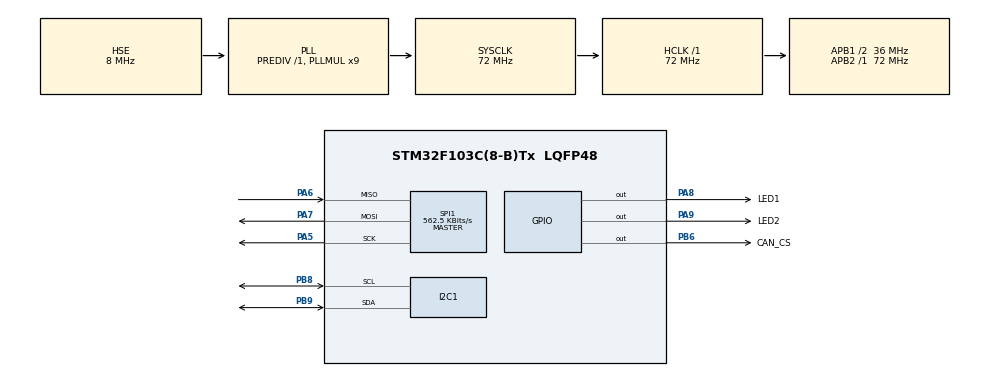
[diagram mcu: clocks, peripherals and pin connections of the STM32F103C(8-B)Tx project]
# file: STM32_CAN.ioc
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Mcu.Family=STM32F1
Mcu.Name=STM32F103C(8-B)Tx
Mcu.Package=LQFP48
NVIC.PriorityGroup=NVIC_PRIORITYGROUP_4
PA5.Mode=Full_Duplex_Master
PA5.Signal=SPI1_SCK
PA6.Mode=Full_Duplex_Master
PA6.Signal=SPI1_MISO
PA7.Mode=Full_Duplex_Master
PA7.Signal=SPI1_MOSI
PA8.GPIO_Label=LED1
PA8.PinState=GPIO_PIN_RESET
PA8.Signal=GPIO_Output
PA9.GPIO_Label=LED2
PA9.Signal=GPIO_Output
PB6.GPIO_Label=CAN_CS
PB6.PinState=GPIO_PIN_SET
PB6.Signal=GPIO_Output
PB8.Mode=I2C
PB8.Signal=I2C1_SCL
PB9.Mode=I2C
PB9.Signal=I2C1_SDA
PD0-OSC_IN.Mode=HSE-External-Oscillator
PD0-OSC_IN.Signal=RCC_OSC_IN
PD1-OSC_OUT.Mode=HSE-External-Oscillator
PD1-OSC_OUT.Signal=RCC_OSC_OUT
ProjectManager.HeapSize=0x200
ProjectManager.StackSize=0x400
ProjectManager.TargetToolchain=STM32CubeIDE
RCC.AHBFreq_Value=72000000
RCC.APB1CLKDivider=RCC_HCLK_DIV2
RCC.APB1Freq_Value=36000000
RCC.APB1TimFreq_Value=72000000
RCC.APB2Freq_Value=72000000
RCC.APB2TimFreq_Value=72000000
RCC.HCLKFreq_Value=72000000
RCC.PLLMUL=RCC_PLL_MUL9
RCC.PLLSourceVirtual=RCC_PLLSOURCE_HSE
RCC.SYSCLKFreq_VALUE=72000000
RCC.SYSCLKSource=RCC_SYSCLKSOURCE_PLLCLK
RCC.USBFreq_Value=72000000
SPI1.BaudRatePrescaler=SPI_BAUDRATEPRESCALER_128
SPI1.CalculateBaudRate=562.5 KBits/s
SPI1.Direction=SPI_DIRECTION_2LINES
SPI1.Mode=SPI_MODE_MASTER
SPI1.VirtualType=VM_MASTER
VP_SYS_VS_ND.Mode=No_Debug
board=custom

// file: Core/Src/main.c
/* USER CODE BEGIN Header */
/**
 ******************************************************************************
 * @file           : main.c
 * @brief          : Main program body
 ******************************************************************************
 * @attention
 *
 * Copyright (c) 2024 STMicroelectronics.
 * All rights reserved.
 *
 * This software is licensed under terms that can be found in the LICENSE file
 * in the root directory of this software component.
 * If no LICENSE file comes with this software, it is provided AS-IS.
 *
 ******************************************************************************
 */
/* USER CODE END Header */
#include <CANSPI.h>
#include <main.h>
#include <stm32f1xx_hal.h>
#include "utils.h"
#include "lcd_i2c.h"
#include "MCP2515.h"

I2C_HandleTypeDef hi2c1;

SPI_HandleTypeDef hspi1;

/* USER CODE BEGIN PV */
/* Private variables ---------------------------------------------------------*/
uCAN_MSG txMessage;
uCAN_MSG rxMessage;

float temperature = 2.2;  // Initial temperature value
float speed = 2.5;       // Initial speed value
float fuel = 2.7;        // Initial fuel value
I2C_HandleTypeDef hi2c1;
/* USER CODE END PV */

void SystemClock_Config(void);
static void MX_GPIO_Init(void);
static void MX_I2C1_Init(void);
static void MX_SPI1_Init(void);
/* USER CODE BEGIN PFP */
/* Private function prototypes -----------------------------------------------*/

/* USER CODE END PFP */

int main(void)
{

  /* MCU Configuration--------------------------------------------------------*/

  /* Reset of all peripherals, Initializes the Flash interface and the Systick. */
  HAL_Init();

  /* Configure the system clock */
  SystemClock_Config();

  /* Initialize all configured peripherals */
  MX_GPIO_Init();
  MX_I2C1_Init();
  MX_SPI1_Init();
  /* USER CODE BEGIN 2 */
	CANSPI_Initialize();
	HD44780_Init(2);
  /* USER CODE END 2 */

  /* Infinite loop */
  /* USER CODE BEGIN WHILE */
	while (1) {
			if (CANSPI_Receive(&rxMessage)) {
				// Process received message
				float receivedTemperature = convertRawToTemperature(
						rxMessage.frame.data0, rxMessage.frame.data1);
				float receivedSpeed = convertRawToSpeed(rxMessage.frame.data2,
						rxMessage.frame.data3);
				float receivedFuel = convertRawToFuel(rxMessage.frame.data4,
						rxMessage.frame.data5);

				// Chuyển hướng hiển thị từ trái sang phải
				HD44780_LeftToRight();

				// In dữ liệu nhận được lên màn hình LCD
				char receivedData[50]; // Đảm bảo đủ kích thước cho chuỗi
				sprintf(receivedData, "Temp: %.2f C, Speed: %.2f km/h, Fuel: %.2f",
						receivedTemperature, receivedSpeed, receivedFuel);
				HD44780_Clear();
				HD44780_PrintStr(receivedData);

				// Modify and transmit the received message
				txMessage.frame.idType = rxMessage.frame.idType;
				txMessage.frame.id = rxMessage.frame.id;
				txMessage.frame.dlc = 0;
				txMessage.frame.data0 = extractIntegerPart(receivedTemperature);
				txMessage.frame.data1 = extractDecimalPart(receivedTemperature);
				txMessage.frame.data2 = extractIntegerPart(receivedSpeed);
				txMessage.frame.data3 = extractDecimalPart(receivedSpeed);
				txMessage.frame.data4 = extractIntegerPart(receivedFuel);
				txMessage.frame.data5 = extractDecimalPart(receivedFuel);
				txMessage.frame.data6 = 0;
				txMessage.frame.data7 = 0;

				CANSPI_Transmit(&txMessage);
			} else {
				// Chuyển hướng hiển thị từ phải sang trái
				HD44780_RightToLeft();

				// In dữ liệu gửi đi lên màn hình LCD
				/*char transmittedData[50]; // Đảm bảo đủ kích thước cho chuỗi
				 sprintf(transmittedData, "T: %f, %f", extractIntegerPart(temperature), temperature);
				 HD44780_Clear();
				 HD44780_PrintStr(transmittedData);*/

				// Prepare and transmit a new message with static data
				txMessage.frame.idType = dSTANDARD_CAN_MSG_ID_2_0B;
				txMessage.frame.id = 0x0A;
				txMessage.frame.dlc = 8;
				txMessage.frame.data0 = 0;
				txMessage.frame.data1 = 0;
				txMessage.frame.data2 = 0;
				txMessage.frame.data3 = 0;
				txMessage.frame.data4 = 0;
				txMessage.frame.data5 = 0;
				txMessage.frame.data6 = 0;
				txMessage.frame.data7 = 0;

				CANSPI_Transmit(&txMessage);
				GPIO_PinState canCsState = HAL_GPIO_ReadPin(CAN_CS_GPIO_Port, CAN_CS_Pin);
				ctrl_status_t ctrlStatus;
				ctrlStatus.ctrl_status = MCP2515_ReadStatus();
				char lcdMessage[50]; // Đảm bảo đủ kích thước cho chuỗi
				sprintf(lcdMessage, "ID: %lu", CANSPI_Transmit(&txMessage));
				HD44780_Clear();
				HD44780_PrintStr(lcdMessage);
			}

			HAL_Delay(1000);
		}
		/* USER CODE END 3 */
	}

void SystemClock_Config(void)
{
  RCC_OscInitTypeDef RCC_OscInitStruct = {0};
  RCC_ClkInitTypeDef RCC_ClkInitStruct = {0};

  /** Initializes the RCC Oscillators according to the specified parameters
  * in the RCC_OscInitTypeDef structure.
  */
  RCC_OscInitStruct.OscillatorType = RCC_OSCILLATORTYPE_HSE;
  RCC_OscInitStruct.HSEState = RCC_HSE_ON;
  RCC_OscInitStruct.HSEPredivValue = RCC_HSE_PREDIV_DIV1;
  RCC_OscInitStruct.HSIState = RCC_HSI_ON;
  RCC_OscInitStruct.PLL.PLLState = RCC_PLL_ON;
  RCC_OscInitStruct.PLL.PLLSource = RCC_PLLSOURCE_HSE;
  RCC_OscInitStruct.PLL.PLLMUL = RCC_PLL_MUL9;
  if (HAL_RCC_OscConfig(&RCC_OscInitStruct) != HAL_OK)
  {
    Error_Handler();
  }

  /** Initializes the CPU, AHB and APB buses clocks
  */
  RCC_ClkInitStruct.ClockType = RCC_CLOCKTYPE_HCLK|RCC_CLOCKTYPE_SYSCLK
                              |RCC_CLOCKTYPE_PCLK1|RCC_CLOCKTYPE_PCLK2;
  RCC_ClkInitStruct.SYSCLKSource = RCC_SYSCLKSOURCE_PLLCLK;
  RCC_ClkInitStruct.AHBCLKDivider = RCC_SYSCLK_DIV1;
  RCC_ClkInitStruct.APB1CLKDivider = RCC_HCLK_DIV2;
  RCC_ClkInitStruct.APB2CLKDivider = RCC_HCLK_DIV1;

  if (HAL_RCC_ClockConfig(&RCC_ClkInitStruct, FLASH_LATENCY_2) != HAL_OK)
  {
    Error_Handler();
  }
}

static void MX_I2C1_Init(void)
{

  hi2c1.Instance = I2C1;
  hi2c1.Init.ClockSpeed = 100000;
  hi2c1.Init.DutyCycle = I2C_DUTYCYCLE_2;
  hi2c1.Init.OwnAddress1 = 0;
  hi2c1.Init.AddressingMode = I2C_ADDRESSINGMODE_7BIT;
  hi2c1.Init.DualAddressMode = I2C_DUALADDRESS_DISABLE;
  hi2c1.Init.OwnAddress2 = 0;
  hi2c1.Init.GeneralCallMode = I2C_GENERALCALL_DISABLE;
  hi2c1.Init.NoStretchMode = I2C_NOSTRETCH_DISABLE;
  if (HAL_I2C_Init(&hi2c1) != HAL_OK)
  {
    Error_Handler();
  }

}

static void MX_SPI1_Init(void)
{

  /* SPI1 parameter configuration*/
  hspi1.Instance = SPI1;
  hspi1.Init.Mode = SPI_MODE_MASTER;
  hspi1.Init.Direction = SPI_DIRECTION_2LINES;
  hspi1.Init.DataSize = SPI_DATASIZE_8BIT;
  hspi1.Init.CLKPolarity = SPI_POLARITY_LOW;
  hspi1.Init.CLKPhase = SPI_PHASE_1EDGE;
  hspi1.Init.NSS = SPI_NSS_SOFT;
  hspi1.Init.BaudRatePrescaler = SPI_BAUDRATEPRESCALER_128;
  hspi1.Init.FirstBit = SPI_FIRSTBIT_MSB;
  hspi1.Init.TIMode = SPI_TIMODE_DISABLE;
  hspi1.Init.CRCCalculation = SPI_CRCCALCULATION_DISABLE;
  hspi1.Init.CRCPolynomial = 10;
  if (HAL_SPI_Init(&hspi1) != HAL_OK)
  {
    Error_Handler();
  }

}

static void MX_GPIO_Init(void)
{
  GPIO_InitTypeDef GPIO_InitStruct = {0};

  /* GPIO Ports Clock Enable */
  __HAL_RCC_GPIOD_CLK_ENABLE();
  __HAL_RCC_GPIOA_CLK_ENABLE();
  __HAL_RCC_GPIOB_CLK_ENABLE();

  /*Configure GPIO pin Output Level */
  HAL_GPIO_WritePin(GPIOA, LED1_Pin|LED2_Pin, GPIO_PIN_RESET);

  /*Configure GPIO pin Output Level */
  HAL_GPIO_WritePin(CAN_CS_GPIO_Port, CAN_CS_Pin, GPIO_PIN_SET);

  /*Configure GPIO pins : LED1_Pin LED2_Pin */
  GPIO_InitStruct.Pin = LED1_Pin|LED2_Pin;
  GPIO_InitStruct.Mode = GPIO_MODE_OUTPUT_PP;
  GPIO_InitStruct.Pull = GPIO_NOPULL;
  GPIO_InitStruct.Speed = GPIO_SPEED_FREQ_LOW;
  HAL_GPIO_Init(GPIOA, &GPIO_InitStruct);

  /*Configure GPIO pin : CAN_CS_Pin */
  GPIO_InitStruct.Pin = CAN_CS_Pin;
  GPIO_InitStruct.Mode = GPIO_MODE_OUTPUT_PP;
  GPIO_InitStruct.Pull = GPIO_NOPULL;
  GPIO_InitStruct.Speed = GPIO_SPEED_FREQ_LOW;
  HAL_GPIO_Init(CAN_CS_GPIO_Port, &GPIO_InitStruct);

}

void Error_Handler(void)
{
	__disable_irq();
	while (1) {
	}
}
